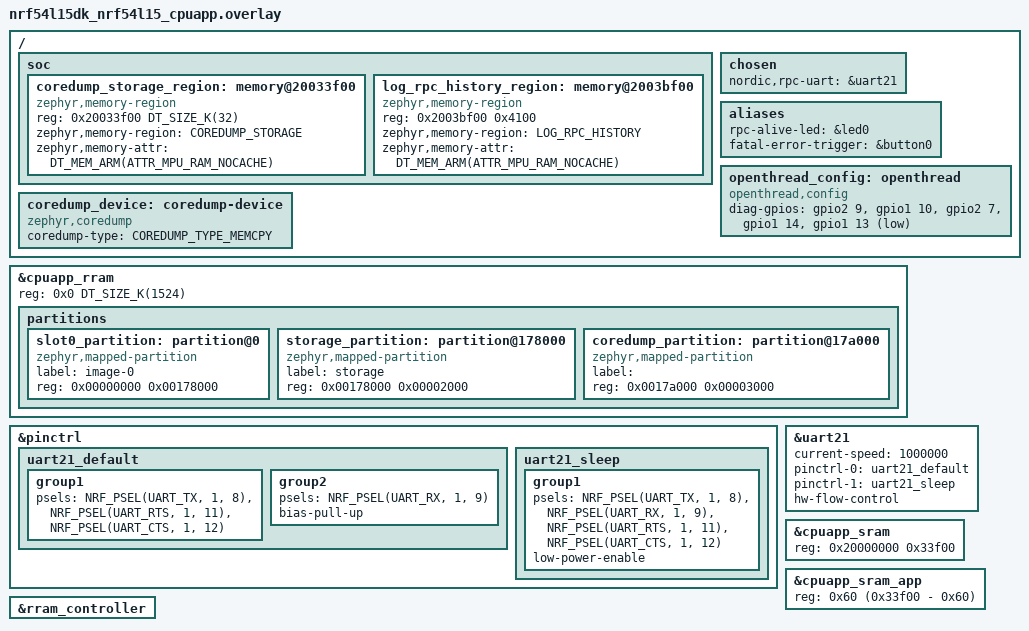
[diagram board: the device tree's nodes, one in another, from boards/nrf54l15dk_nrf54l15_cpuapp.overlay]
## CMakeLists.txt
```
#
# Copyright (c) 2024 Nordic Semiconductor ASA
#
# SPDX-License-Identifier: LicenseRef-Nordic-5-Clause
#
cmake_minimum_required(VERSION 3.20.0)

find_package(Zephyr REQUIRED HINTS $ENV{ZEPHYR_BASE})

# manually enable NRF54L_CONFIGURATION_56_ENABLE until nrfx 4.0.0 is integrated
if ((CONFIG_SOC_SERIES_NRF54LX) AND (CONFIG_NRF_802154_SOURCE_INTERNAL))
    target_compile_definitions(nrf-802154-driver-interface INTERFACE NRF54L_CONFIGURATION_56_ENABLE=1)
endif()

# # Do not include obfuscated symbols in case of building from sources
if (CONFIG_MPSL_BUILD_TYPE_SRC_DEBUG)
  target_compile_definitions(nrf-802154-driver-interface INTERFACE OBFUSCATE_LIBMPSL_PROTOCOL_DEFINES_H__=1)
endif()

project(protocols_serialization_server)

# NORDIC SDK APP START
target_sources(app PRIVATE src/main.c)

if(CONFIG_NRF_PS_SERVER_FATAL_ERROR_TRIGGER)
  target_sources(app PRIVATE src/fatal_error_trigger.c)
endif()


if(CONFIG_NRF_PS_SERVER_HEALTH_MONITOR)
  target_sources(app PRIVATE src/hot_main.c)
endif()

if(CONFIG_NRF_PS_SERVER_RPC_ALIVE_LED)
  # Wrap z_fatal_error to turn off the RPC alive LED on fatal error
  target_link_options(app INTERFACE -Wl,--wrap=z_fatal_error)
endif()
# NORDIC SDK APP END

# Link OpenThread CLI even though OPENTHREAD_SHELL is not selected
if(CONFIG_OPENTHREAD_RPC)
  target_link_libraries(zephyr PRIVATE openthread-cli-ftd)
endif()
```

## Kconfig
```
#
# Copyright (c) 2024 Nordic Semiconductor ASA
#
# SPDX-License-Identifier: LicenseRef-Nordic-5-Clause
#

menu "Protocols serialization server"

config NRF_PS_SERVER_FATAL_ERROR_TRIGGER
	bool "Fatal error trigger"
	depends on $(dt_alias_enabled,fatal-error-trigger)
	help
	  Enables triggering a fatal error by pressing the button selected with
	  "/aliases/fatal-error-trigger" DTS property. This feature can be used
	  to generate a core dump into a flash/RRAM partition. The core dump can
	  then be retrieved by the RPC client using the "Logging over RPC"
	  library.

config NRF_PS_SERVER_RPC_ALIVE_LED
	bool "RPC alive LED"
	default y
	depends on $(dt_alias_enabled,rpc-alive-led)
	help
	  Turns on the LED selected with "/aliases/rpc-alive-led" DTS property
	  when the UART transport is alive and ready to receive nRF RPC packets.

config NRF5_UICR_EUI64_ENABLE
	default y if (SOC_NRF54L15 && OPENTHREAD)

module = NRF_PS_SERVER
module-str = nrf_ps_server
source "$(ZEPHYR_BASE)/subsys/logging/Kconfig.template.log_config"

endmenu # "Protocols serialization server"

config ZMS
	default y if (SOC_FLASH_NRF_RRAM || SOC_FLASH_NRF_MRAM)

config NVS
	default y if !(SOC_FLASH_NRF_RRAM || SOC_FLASH_NRF_MRAM)

config SHELL_BACKEND_SERIAL
	default n if NRF_RPC_UTILS_REMOTE_SHELL

if LOG

choice LOG_MODE
	default LOG_MODE_DEFERRED
endchoice

config LOG_BUFFER_SIZE
	default 8192

config LOG_FUNC_NAME_PREFIX_DBG
	default n

config LOG_BACKEND_RTT
	default n

config LOG_BACKEND_UART
	default n

endif # LOG

if LOG_BACKEND_UART_ASYNC

# Using UART async API by the logging backend significantly reduces CPU load imposed by logging.
# To make it work, the corresponding UART instance needs to be configured to use the async API
# as well, which requires disabling the default, interrupt-driven API.
# Do it for all possible UART instances for the supported nRF54L SoCs.

uart_num = 0
rsource "Kconfig.zephyr_console_async"

uart_num = 1
rsource "Kconfig.zephyr_console_async"

uart_num = 00
rsource "Kconfig.zephyr_console_async"

uart_num = 20
rsource "Kconfig.zephyr_console_async"

uart_num = 21
rsource "Kconfig.zephyr_console_async"

uart_num = 22
rsource "Kconfig.zephyr_console_async"

uart_num = 30
rsource "Kconfig.zephyr_console_async"

endif # LOG_BACKEND_UART_ASYNC

if SOC_NRF54L15

config BT_LONG_WQ_STACK_SIZE
	default 2048

choice TRUSTED_STORAGE_BACKEND_AEAD_KEY
	default TRUSTED_STORAGE_BACKEND_AEAD_KEY_HASH_UID if TRUSTED_STORAGE_BACKEND_AEAD
endchoice

endif # SOC_NRF54L15

menu "Zephyr Kernel"
source "Kconfig.zephyr"
endmenu
```

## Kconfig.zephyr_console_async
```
#
# Copyright (c) 2025 Nordic Semiconductor ASA
#
# SPDX-License-Identifier: LicenseRef-Nordic-5-Clause
#

DT_CHOSEN_ZEPHYR_CONSOLE := zephyr,console

config UART_$(uart_num)_INTERRUPT_DRIVEN
	default n
	depends on $(dt_nodelabel_enabled,uart$(uart_num))
	depends on "$(dt_nodelabel_path,uart$(uart_num))" = "$(dt_chosen_path,$(DT_CHOSEN_ZEPHYR_CONSOLE))"
```

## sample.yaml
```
sample:
  name: Protocols serialization server sample
  description: Demonstrates serialization of Bluetooth LE and OpenThread API using
    nRF RPC

common:
  sysbuild: true
  build_only: true
  platform_allow:
    - nrf54l15dk/nrf54l15/cpuapp
    - nrf54lm20dk/nrf54lm20a/cpuapp
    - nrf54lm20dk/nrf54lm20b/cpuapp
  integration_platforms:
    - nrf54l15dk/nrf54l15/cpuapp
    - nrf54lm20dk/nrf54lm20a/cpuapp
    - nrf54lm20dk/nrf54lm20b/cpuapp
  tags:
    - ci_build
    - ci_samples_nrf_rpc
  extra_args:
    - SNIPPET_ROOT="."

tests:
  sample.nrf_rpc.protocols_serialization.server.rpc_ble:
    extra_args:
      - EXTRA_CONF_FILE=ble.conf
  sample.nrf_rpc.protocols_serialization.server.rpc_ot:
    extra_args:
      - EXTRA_CONF_FILE=openthread.conf
  sample.nrf_rpc.protocols_serialization.server.rpc:
    extra_args:
      - EXTRA_DTC_OVERLAY_FILE=coex.overlay
      - EXTRA_CONF_FILE="ble.conf;openthread.conf;verbose.conf;log_rpc.conf;coex.conf"
  sample.nrf_rpc.protocols_serialization.server.rpc_ci:
    extra_args:
      - SNIPPET="ci-shell"
      - EXTRA_DTC_OVERLAY_FILE=coex.overlay
      - EXTRA_CONF_FILE="ble.conf;openthread.conf;verbose.conf;log_rpc.conf;coex.conf"
    extra_configs:
      - CONFIG_NRF_RPC_UTILS_CRASH_GEN=y
      - CONFIG_OPENTHREAD_RPC_ERASE_SETTINGS=y
```

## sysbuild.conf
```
SB_CONFIG_PARTITION_MANAGER=n
SB_CONFIG_BOOTLOADER_MCUBOOT=y
SB_CONFIG_MCUBOOT_MODE_SINGLE_APP=y
SB_CONFIG_BOOT_SIGNATURE_TYPE_NONE=y
```

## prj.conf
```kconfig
#
# Copyright (c) 2024 Nordic Semiconductor
#
# SPDX-License-Identifier: LicenseRef-Nordic-5-Clause
#
CONFIG_HEAP_MEM_POOL_SIZE=4096

CONFIG_NRF_RPC=y
CONFIG_NRF_RPC_CBOR=y
CONFIG_NRF_RPC_ZCBOR_BACKUPS=1
CONFIG_NRF_RPC_THREAD_STACK_SIZE=4096
CONFIG_NRF_RPC_GROUP_INIT_WAIT_TIME=-1
CONFIG_NRF_RPC_UART_TRANSPORT=y
CONFIG_NRF_RPC_UART_RELIABLE=y

CONFIG_UART_LINE_CTRL=y
CONFIG_UART_INTERRUPT_DRIVEN=y

CONFIG_NRF_RPC_UTILS=y
CONFIG_NRF_RPC_UTILS_SERVER=y
CONFIG_NRF_RPC_UTILS_DEV_INFO=y
CONFIG_NRF_RPC_UTILS_REMOTE_SHELL=y
CONFIG_NRF_RPC_UTILS_SYSTEM_HEALTH=y
CONFIG_NRF_RPC_UTILS_NESTED_CMD_TEST=y

CONFIG_USE_DT_CODE_PARTITION=y
CONFIG_SETTINGS=y
CONFIG_FLASH=y
CONFIG_FLASH_MAP=y
```

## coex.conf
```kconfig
#
# Copyright (c) 2026 Nordic Semiconductor
#
# SPDX-License-Identifier: LicenseRef-Nordic-5-Clause
#
# Enables MPSL Software Coexistence for this sample.
#
# Note: This sample requires applying :file:`coex.overlay` explicitly (pass it
# via EXTRA_DTC_OVERLAY_FILE) together with this Kconfig fragment.
#

CONFIG_MPSL_CX=y
CONFIG_MPSL_CX_SOFTWARE=y
```

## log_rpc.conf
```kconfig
#
# Copyright (c) 2024 Nordic Semiconductor
#
# SPDX-License-Identifier: LicenseRef-Nordic-5-Clause
#

CONFIG_LOG=y
CONFIG_LOG_BACKEND_RPC=y
CONFIG_LOG_BACKEND_RPC_CRASH_LOG=y
CONFIG_LOG_BACKEND_RPC_HISTORY=y
CONFIG_LOG_BACKEND_RPC_ECHO=y

# Core dump in dedicated noinit SRAM (see board overlay coredump_storage_region)
CONFIG_DEBUG_COREDUMP=y
CONFIG_DEBUG_COREDUMP_BACKEND_OTHER=y
CONFIG_DEBUG_COREDUMP_BACKEND_NRF_RAM_REGION=y
CONFIG_DEBUG_COREDUMP_MEMORY_DUMP_THREADS=y
CONFIG_DEBUG_COREDUMP_THREADS_METADATA=y
CONFIG_DEBUG_COREDUMP_THREAD_STACK_TOP=y
CONFIG_DEBUG_COREDUMP_THREAD_STACK_TOP_LIMIT=256
CONFIG_EXTRA_EXCEPTION_INFO=y
CONFIG_COREDUMP_DEVICE=y

# nRF RPC requires slightly bigger stack than default
CONFIG_LOG_PROCESS_THREAD_STACK_SIZE=1024

# Enable OpenThread logs along with logging over RPC
CONFIG_OPENTHREAD_DEBUG=y
CONFIG_OPENTHREAD_LOG_LEVEL_INFO=y

# Enable fatal error trigger for testing the crash log feature
CONFIG_NRF_PS_SERVER_FATAL_ERROR_TRIGGER=y
```

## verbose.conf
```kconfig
#
# Copyright (c) 2024 Nordic Semiconductor
#
# SPDX-License-Identifier: LicenseRef-Nordic-5-Clause
#
# Development-oriented options: asserts, UART logging (async), and DBG level
# for this sample and nRF RPC modules. For manual use, pass e.g.:
#   -- -DEXTRA_CONF_FILE=verbose.conf

# Enable asserts
CONFIG_ASSERT=y

# Enable UART console. Use async API to reduce CPU load.
CONFIG_LOG=y
CONFIG_LOG_BACKEND_UART=y
CONFIG_UART_ASYNC_API=y
CONFIG_LOG_BACKEND_UART_ASYNC=y

# Verbose (DBG) logging for this sample and RPC stack
CONFIG_NRF_PS_SERVER_LOG_LEVEL_DBG=y
CONFIG_NRF_RPC_TR_LOG_LEVEL_DBG=y
CONFIG_NRF_RPC_LOG_LEVEL_DBG=y
CONFIG_NRF_RPC_OS_LOG_LEVEL_DBG=y
CONFIG_NRF_RPC_DETAILED_ERROR_REPORTING=y
CONFIG_NRF_RPC_UTILS_RRAM_WEAR_TEST=y
```

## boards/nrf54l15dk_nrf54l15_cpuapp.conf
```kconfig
#
# Copyright (c) 2024 Nordic Semiconductor
#
# SPDX-License-Identifier: LicenseRef-Nordic-5-Clause
#
CONFIG_MAIN_STACK_SIZE=4196
CONFIG_NRF_RPC_THREAD_STACK_SIZE=6144

# USE HASH UID instead of HUK for this sample, because Partition Manager is not available
CONFIG_TRUSTED_STORAGE_BACKEND_AEAD_KEY_HASH_UID=y

# Workaround required as Zephyr L2 implies usage of NVS backend for settings.
# It should be removed once the proper fix will be applied in Zephyr.
CONFIG_NVS=n
```

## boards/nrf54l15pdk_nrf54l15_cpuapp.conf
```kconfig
#
# Copyright (c) 2024 Nordic Semiconductor
#
# SPDX-License-Identifier: LicenseRef-Nordic-5-Clause
#
CONFIG_MAIN_STACK_SIZE=4196
CONFIG_NRF_RPC_THREAD_STACK_SIZE=6144

# USE HASH UID instead of HUK for this sample, because Partition Manager is not available
CONFIG_TRUSTED_STORAGE_BACKEND_AEAD_KEY_HASH_UID=y
```

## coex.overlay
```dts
/*
 * Copyright (c) 2026 Nordic Semiconductor ASA
 *
 * SPDX-License-Identifier: LicenseRef-Nordic-5-Clause
 */

/ {
	nrf_radio_coex: software-coex {
		compatible = "nordic,software-coex";
		status = "okay";
	};
};
```

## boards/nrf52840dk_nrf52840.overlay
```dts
/*
 * Copyright (c) 2024 Nordic Semiconductor ASA
 *
 * SPDX-License-Identifier: LicenseRef-Nordic-5-Clause
 */
#include <zephyr/dt-bindings/memory-attr/memory-attr-arm.h>

/* Log RPC history + optional RAM coredump. */
/ {
	soc {
		coredump_storage_region: memory@20033f00 {
			compatible = "zephyr,memory-region", "mmio-sram";
			reg = <0x20033f00 DT_SIZE_K(32)>;
			zephyr,memory-region = "COREDUMP_STORAGE";
			zephyr,memory-attr = <DT_MEM_ARM(ATTR_MPU_RAM_NOCACHE)>;
			status = "okay";
		};

		/* 0x4100 = 0x4000 buffer + 0x100 control; ends at 0x20040000 */
		log_rpc_history_region: memory@2003bf00 {
			compatible = "zephyr,memory-region", "mmio-sram";
			reg = <0x2003bf00 0x4100>;
			zephyr,memory-region = "LOG_RPC_HISTORY";
			zephyr,memory-attr = <DT_MEM_ARM(ATTR_MPU_RAM_NOCACHE)>;
			status = "okay";
		};
	};
};

/* Shorter sram0 (0x33f00); 32 KiB COREDUMP_STORAGE; top 0x4100 = log history. */
&sram0 {
	reg = <0x20000000 0x33f00>;
};

/ {
	chosen {
		nordic,rpc-uart = &uart1;
	};

	aliases {
		rpc-alive-led = &led0;
		fatal-error-trigger = &button0;
	};

	openthread_config: openthread {
		compatible = "openthread,config";
		diag-gpios = <&gpio0 13 GPIO_ACTIVE_LOW>,
			     <&gpio0 14 GPIO_ACTIVE_LOW>,
			     <&gpio0 15 GPIO_ACTIVE_LOW>,
			     <&gpio0 16 GPIO_ACTIVE_LOW>,
			     <&gpio0 11 (GPIO_PULL_UP | GPIO_ACTIVE_LOW)>,
			     <&gpio0 12 (GPIO_PULL_UP | GPIO_ACTIVE_LOW)>,
			     <&gpio0 24 (GPIO_PULL_UP | GPIO_ACTIVE_LOW)>,
			     <&gpio0 25 (GPIO_PULL_UP | GPIO_ACTIVE_LOW)>;
	};

	coredump_device: coredump-device {
		compatible = "zephyr,coredump";
		coredump-type = "COREDUMP_TYPE_MEMCPY";
		status = "okay";
	};
};

/delete-node/ &boot_partition;
/delete-node/ &slot0_partition;
/delete-node/ &slot1_partition;
/delete-node/ &storage_partition;

&flash0 {
	partitions {
		slot0_partition: partition@0 {
			compatible = "zephyr,mapped-partition";
			label = "image-0";
			reg = <0x00000000 0x000fb000>;
		};

		storage_partition: partition@fb000 {
			compatible = "zephyr,mapped-partition";
			label = "storage";
			reg = <0x000fb000 0x00002000>;
		};

		coredump_partition: partition@fd000 {
			compatible = "zephyr,mapped-partition";
			label = "";
			reg = <0x000fd000 0x00003000>;
		};
	};
};

&uart1 {
	status = "okay";
	hw-flow-control;
	current-speed = <1000000>;
};

&uart1_default {
	group1 {
		psels = <NRF_PSEL(UART_TX, 1, 2)>,
			<NRF_PSEL(UART_RTS, 1, 3)>,
			<NRF_PSEL(UART_CTS, 1, 4)>;
	};

	group2 {
		psels = <NRF_PSEL(UART_RX, 1, 1)>;
		bias-pull-up;
	};
};

&uart1_sleep {
	group1 {
		psels = <NRF_PSEL(UART_RX, 1, 1)>,
			<NRF_PSEL(UART_TX, 1, 2)>,
			<NRF_PSEL(UART_RTS, 1, 3)>,
			<NRF_PSEL(UART_CTS, 1, 4)>;
		low-power-enable;
	};
};
```

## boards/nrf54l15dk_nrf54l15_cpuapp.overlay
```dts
/*
 * Copyright (c) 2024 Nordic Semiconductor ASA
 *
 * SPDX-License-Identifier: LicenseRef-Nordic-5-Clause
 */

#include <zephyr/dt-bindings/memory-attr/memory-attr-arm.h>

/* Log RPC history: one fixed region (buffer + control + magic) at top of 256 KB SRAM.
 * Layout: [16 KB buffer][pbuf struct + magic]. MPU: non-executable, non-cacheable.
 * Coredump: 32 KB noinit SRAM just below log history
 * (CONFIG_DEBUG_COREDUMP_BACKEND_NRF_RAM_REGION).
 */
/ {
	soc {
		coredump_storage_region: memory@20033f00 {
			compatible = "zephyr,memory-region", "mmio-sram";
			reg = <0x20033f00 DT_SIZE_K(32)>;
			zephyr,memory-region = "COREDUMP_STORAGE";
			zephyr,memory-attr = <DT_MEM_ARM(ATTR_MPU_RAM_NOCACHE)>;
			status = "okay";
		};

		/* 0x4100 = 0x4000 buffer + 0x100 control; base so region ends at 0x20040000 */
		log_rpc_history_region: memory@2003bf00 {
			compatible = "zephyr,memory-region", "mmio-sram";
			reg = <0x2003bf00 0x4100>;
			zephyr,memory-region = "LOG_RPC_HISTORY";
			zephyr,memory-attr = <DT_MEM_ARM(ATTR_MPU_RAM_NOCACHE)>;
			status = "okay";
		};
	};
};

/ {
	chosen {
		nordic,rpc-uart = &uart21;
	};

	aliases {
		rpc-alive-led = &led0;
		fatal-error-trigger = &button0;

		/* delete all buttons except button0 to free GPIO pins assigned to uart21 below */
		/delete-property/ sw1;
		/delete-property/ sw2;
		/delete-property/ sw3;
	};

	openthread_config: openthread {
		compatible = "openthread,config";
		diag-gpios = <&gpio2 9 GPIO_ACTIVE_HIGH>,
			     <&gpio1 10 GPIO_ACTIVE_HIGH>,
			     <&gpio2 7 GPIO_ACTIVE_HIGH>,
			     <&gpio1 14 GPIO_ACTIVE_HIGH>,
			     <&gpio1 13 (GPIO_PULL_UP | GPIO_ACTIVE_LOW)>;
	};

	coredump_device: coredump-device {
		compatible = "zephyr,coredump";
		coredump-type = "COREDUMP_TYPE_MEMCPY";
		status = "okay";
	};
};

/delete-node/ &button1;
/delete-node/ &button2;
/delete-node/ &button3;
/delete-node/ &boot_partition;
/delete-node/ &slot0_partition;
/delete-node/ &slot1_partition;
/delete-node/ &storage_partition;

/* restore full RRAM and SRAM space - by default some parts are dedicated to FLRP */
&cpuapp_rram {
	reg = <0x0 DT_SIZE_K(1524)>;

	partitions {
		slot0_partition: partition@0 {
			compatible = "zephyr,mapped-partition";
			label = "image-0";
			reg = <0x00000000 0x00178000>;
		};

		storage_partition: partition@178000 {
			compatible = "zephyr,mapped-partition";
			label = "storage";
			reg = <0x00178000 0x00002000>;
		};

		coredump_partition: partition@17a000 {
			compatible = "zephyr,mapped-partition";
			label = "";
			reg = <0x0017a000 0x00003000>;
		};
	};
};

&pinctrl {
	uart21_default: uart21_default {
		group1 {
			psels = <NRF_PSEL(UART_TX, 1, 8)>,
				<NRF_PSEL(UART_RTS, 1, 11)>,
				<NRF_PSEL(UART_CTS, 1, 12)>;
		};

		group2 {
			psels = <NRF_PSEL(UART_RX, 1, 9)>;
			bias-pull-up;
		};
	};

	uart21_sleep: uart21_sleep {
		group1 {
			psels = <NRF_PSEL(UART_TX, 1, 8)>,
				<NRF_PSEL(UART_RX, 1, 9)>,
				<NRF_PSEL(UART_RTS, 1, 11)>,
				<NRF_PSEL(UART_CTS, 1, 12)>;
			low-power-enable;
		};
	};
};

&uart21 {
	status = "okay";
	current-speed = <1000000>;
	pinctrl-0 = <&uart21_default>;
	pinctrl-1 = <&uart21_sleep>;
	pinctrl-names = "default", "sleep";
	hw-flow-control;
};

/* restore full RRAM and SRAM space - by default some parts are dedicated to FLRP */
&cpuapp_rram {
	reg = <0x0 DT_SIZE_K(1524)>;
};

/* Shorter cpuapp_sram (0x33f00); 32 KB COREDUMP_STORAGE; top 0x4100 = log history. */
&cpuapp_sram {
	reg = <0x20000000 0x33f00>;
	ranges = <0x0 0x20000000 0x33f00>;
};

&cpuapp_sram_app {
	reg = <0x60 (0x33f00 - 0x60)>;
};

&rram_controller {
	/delete-node/ cpuflpr_sram;
	/delete-node/ cpuflpr_rram;
};
```

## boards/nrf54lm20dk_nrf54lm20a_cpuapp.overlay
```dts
/*
 * Copyright (c) 2025 Nordic Semiconductor ASA
 *
 * SPDX-License-Identifier: LicenseRef-Nordic-5-Clause
 */

#include <zephyr/dt-bindings/memory-attr/memory-attr-arm.h>

/* Log RPC history + RAM coredump at top of cpuapp SRAM. */
/ {
	soc {
		coredump_storage_region: memory@20073b00 {
			compatible = "zephyr,memory-region", "mmio-sram";
			reg = <0x20073b00 DT_SIZE_K(32)>;
			zephyr,memory-region = "COREDUMP_STORAGE";
			zephyr,memory-attr = <DT_MEM_ARM(ATTR_MPU_RAM_NOCACHE)>;
			status = "okay";
		};

		/* Reserve top 0x4100 ending @ 0x2007fc00 */
		log_rpc_history_region: memory@2007bb00 {
			compatible = "zephyr,memory-region", "mmio-sram";
			reg = <0x2007bb00 0x4100>;
			zephyr,memory-region = "LOG_RPC_HISTORY";
			zephyr,memory-attr = <DT_MEM_ARM(ATTR_MPU_RAM_NOCACHE)>;
			status = "okay";
		};
	};
};

/* App SRAM minus coredump and log history (511 KB - 0x8000 - 0x4100 = 0x73b00). */
&cpuapp_sram_app {
	reg = <0x60 (0x73b00 - 0x60)>;
};

/ {
	chosen {
		nordic,rpc-uart = &uart21;
	};

	aliases {
		rpc-alive-led = &led0;
		fatal-error-trigger = &button0;

		/* delete all buttons except button0 to free GPIO pins assigned to uart21 below */
		/delete-property/ sw1;
		/delete-property/ sw2;
		/delete-property/ sw3;
	};

	coredump_device: coredump-device {
		compatible = "zephyr,coredump";
		coredump-type = "COREDUMP_TYPE_MEMCPY";
		status = "okay";
	};
};

/delete-node/ &button1;
/delete-node/ &button2;
/delete-node/ &button3;
/delete-node/ &boot_partition;
/delete-node/ &slot0_partition;
/delete-node/ &slot1_partition;
/delete-node/ &storage_partition;

&cpuapp_rram {
	reg = <0x0 DT_SIZE_K(2036)>;

	partitions {
		slot0_partition: partition@0 {
			compatible = "zephyr,mapped-partition";
			label = "image-0";
			reg = <0x00000000 0x001f8000>;
		};

		storage_partition: partition@1f8000 {
			compatible = "zephyr,mapped-partition";
			label = "storage";
			reg = <0x001f8000 0x00002000>;
		};

		coredump_partition: partition@1fa000 {
			compatible = "zephyr,mapped-partition";
			label = "";
			reg = <0x001fa000 0x00003000>;
		};
	};
};

&pinctrl {
	uart21_default: uart21_default {
		group1 {
			psels = <NRF_PSEL(UART_TX, 1, 8)>,
				<NRF_PSEL(UART_RTS, 1, 11)>,
				<NRF_PSEL(UART_CTS, 1, 12)>;
		};

		group2 {
			psels = <NRF_PSEL(UART_RX, 1, 9)>;
			bias-pull-up;
		};
	};

	uart21_sleep: uart21_sleep {
		group1 {
			psels = <NRF_PSEL(UART_TX, 1, 8)>,
				<NRF_PSEL(UART_RX, 1, 9)>,
				<NRF_PSEL(UART_RTS, 1, 11)>,
				<NRF_PSEL(UART_CTS, 1, 12)>;
			low-power-enable;
		};
	};
};

&uart21 {
	status = "okay";
	current-speed = <1000000>;
	pinctrl-0 = <&uart21_default>;
	pinctrl-1 = <&uart21_sleep>;
	pinctrl-names = "default", "sleep";
	hw-flow-control;
};
```

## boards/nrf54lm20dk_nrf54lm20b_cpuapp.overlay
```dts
/*
 * Copyright (c) 2026 Nordic Semiconductor ASA
 *
 * SPDX-License-Identifier: LicenseRef-Nordic-5-Clause
 */

#include <zephyr/dt-bindings/memory-attr/memory-attr-arm.h>

/* Log RPC history + RAM coredump at top of cpuapp SRAM. */
/ {
	soc {
		coredump_storage_region: memory@20073b00 {
			compatible = "zephyr,memory-region", "mmio-sram";
			reg = <0x20073b00 DT_SIZE_K(32)>;
			zephyr,memory-region = "COREDUMP_STORAGE";
			zephyr,memory-attr = <DT_MEM_ARM(ATTR_MPU_RAM_NOCACHE)>;
			status = "okay";
		};

		/* Reserve top 0x4100 ending @ 0x2007fc00 */
		log_rpc_history_region: memory@2007bb00 {
			compatible = "zephyr,memory-region", "mmio-sram";
			reg = <0x2007bb00 0x4100>;
			zephyr,memory-region = "LOG_RPC_HISTORY";
			zephyr,memory-attr = <DT_MEM_ARM(ATTR_MPU_RAM_NOCACHE)>;
			status = "okay";
		};
	};
};

/* App SRAM minus coredump and log history (511 KB - 0x8000 - 0x4100 = 0x73b00). */
&cpuapp_sram_app {
	reg = <0x60 (0x73b00 - 0x60)>;
};

/ {
	chosen {
		nordic,rpc-uart = &uart21;
	};

	aliases {
		rpc-alive-led = &led0;
		fatal-error-trigger = &button0;

		/* delete all buttons except button0 to free GPIO pins assigned to uart21 below */
		/delete-property/ sw1;
		/delete-property/ sw2;
		/delete-property/ sw3;
	};

	coredump_device: coredump-device {
		compatible = "zephyr,coredump";
		coredump-type = "COREDUMP_TYPE_MEMCPY";
		status = "okay";
	};
};

/delete-node/ &button1;
/delete-node/ &button2;
/delete-node/ &button3;
/delete-node/ &boot_partition;
/delete-node/ &slot0_partition;
/delete-node/ &slot1_partition;
/delete-node/ &storage_partition;

&cpuapp_rram {
	reg = <0x0 DT_SIZE_K(2036)>;

	partitions {
		slot0_partition: partition@0 {
			compatible = "zephyr,mapped-partition";
			label = "image-0";
			reg = <0x00000000 0x001f8000>;
		};

		storage_partition: partition@1f8000 {
			compatible = "zephyr,mapped-partition";
			label = "storage";
			reg = <0x001f8000 0x00002000>;
		};

		coredump_partition: partition@1fa000 {
			compatible = "zephyr,mapped-partition";
			label = "";
			reg = <0x001fa000 0x00003000>;
		};
	};
};

&pinctrl {
	uart21_default: uart21_default {
		group1 {
			psels = <NRF_PSEL(UART_TX, 1, 8)>,
				<NRF_PSEL(UART_RTS, 1, 11)>,
				<NRF_PSEL(UART_CTS, 1, 12)>;
		};

		group2 {
			psels = <NRF_PSEL(UART_RX, 1, 9)>;
			bias-pull-up;
		};
	};

	uart21_sleep: uart21_sleep {
		group1 {
			psels = <NRF_PSEL(UART_TX, 1, 8)>,
				<NRF_PSEL(UART_RX, 1, 9)>,
				<NRF_PSEL(UART_RTS, 1, 11)>,
				<NRF_PSEL(UART_CTS, 1, 12)>;
			low-power-enable;
		};
	};
};

&uart21 {
	status = "okay";
	current-speed = <1000000>;
	pinctrl-0 = <&uart21_default>;
	pinctrl-1 = <&uart21_sleep>;
	pinctrl-names = "default", "sleep";
	hw-flow-control;
};
```

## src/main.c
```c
/*
 * Copyright (c) 2024 Nordic Semiconductor ASA
 *
 * SPDX-License-Identifier: LicenseRef-Nordic-5-Clause
 */

#include <zephyr/drivers/gpio.h>
#include <zephyr/logging/log.h>

#include <nrf_rpc.h>

LOG_MODULE_REGISTER(nrf_ps_server, CONFIG_NRF_PS_SERVER_LOG_LEVEL);

static void err_handler(const struct nrf_rpc_err_report *report)
{
	LOG_ERR("nRF RPC error %d ocurred. See nRF RPC logs for more details", report->code);
}

#ifdef CONFIG_NRF_PS_SERVER_RPC_ALIVE_LED
void nrf_rpc_uart_initialized_hook(const struct device *uart_dev)
{
	const struct gpio_dt_spec alive_gpio = GPIO_DT_SPEC_GET(DT_ALIAS(rpc_alive_led), gpios);
	int ret;

	__ASSERT_NO_MSG(uart_dev == DEVICE_DT_GET(DT_CHOSEN(nordic_rpc_uart)));
	ret = gpio_pin_configure_dt(&alive_gpio, GPIO_OUTPUT_ACTIVE);

	if (ret) {
		LOG_ERR("Failed to configure RPC alive GPIO: %d", ret);
	}
}

void __real_z_fatal_error(unsigned int reason, const struct arch_esf *esf);

void __wrap_z_fatal_error(unsigned int reason, const struct arch_esf *esf)
{
	const struct gpio_dt_spec alive_gpio = GPIO_DT_SPEC_GET(DT_ALIAS(rpc_alive_led), gpios);

	(void)gpio_pin_configure_dt(&alive_gpio, GPIO_OUTPUT_INACTIVE);

	__real_z_fatal_error(reason, esf);
}
#endif

int main(void)
{
	int ret;

	LOG_INF("Initializing RPC server");

	ret = nrf_rpc_init(err_handler);

	if (ret != 0) {
		LOG_ERR("RPC init failed");
	}

	LOG_INF("RPC server ready");

	return 0;
}
```

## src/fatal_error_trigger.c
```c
/*
 * Copyright (c) 2024 Nordic Semiconductor ASA
 *
 * SPDX-License-Identifier: LicenseRef-Nordic-5-Clause
 */

#include <zephyr/drivers/gpio.h>
#include <zephyr/init.h>
#include <zephyr/logging/log.h>
#include <zephyr/sys/util_macro.h>

LOG_MODULE_DECLARE(nrf_ps_server, CONFIG_NRF_PS_SERVER_LOG_LEVEL);

const struct gpio_dt_spec gpio_pin = GPIO_DT_SPEC_GET(DT_ALIAS(fatal_error_trigger), gpios);
static struct gpio_callback gpio_cb;

static void trigger_handler(const struct device *port, struct gpio_callback *cb,
			    gpio_port_pins_t pins)
{
	ARG_UNUSED(port);
	ARG_UNUSED(cb);
	ARG_UNUSED(pins);

	LOG_ERR("Fatal error button pressed - triggering k_oops");
	k_oops();
}

static int trigger_init(void)
{
	int rc;

	if (!gpio_is_ready_dt(&gpio_pin)) {
		return -ENODEV;
	}

	rc = gpio_pin_configure_dt(&gpio_pin, GPIO_INPUT);
	if (rc) {
		return rc;
	}

	gpio_init_callback(&gpio_cb, trigger_handler, BIT(gpio_pin.pin));

	rc = gpio_add_callback_dt(&gpio_pin, &gpio_cb);
	if (rc) {
		return rc;
	}

	rc = gpio_pin_interrupt_configure_dt(&gpio_pin, GPIO_INT_EDGE_TO_ACTIVE);
	if (rc) {
		return rc;
	}

	return 0;
}

SYS_INIT(trigger_init, APPLICATION, CONFIG_APPLICATION_INIT_PRIORITY);
```

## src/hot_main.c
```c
/*
 * Copyright (c) 2024 Nordic Semiconductor ASA
 *
 * SPDX-License-Identifier: LicenseRef-Nordic-5-Clause
 */

#include <zephyr/kernel.h>
#include <zephyr/logging/log.h>
#include <health_monitor.h>

LOG_MODULE_REGISTER(nrf_ps_server_main, CONFIG_NRF_PS_SERVER_LOG_LEVEL);


#define WORK_STACK_SIZE 1024
#define WORK_PRIORITY   K_LOWEST_APPLICATION_THREAD_PRIO

K_THREAD_STACK_DEFINE(hotpot_workqueue_stack, WORK_STACK_SIZE);

struct k_work_q hotpork_workq;

static int init_hotpot_workqueue(void)
{
	k_work_queue_init(&hotpork_workq);

	k_work_queue_start(&hotpork_workq,
			    hotpot_workqueue_stack,
			    K_THREAD_STACK_SIZEOF(hotpot_workqueue_stack),
			    WORK_PRIORITY,
			    NULL);

	health_monitor_init(&hotpork_workq);

	LOG_INF("Initialized application workqueue.");

	return 0;
}

SYS_INIT(init_hotpot_workqueue, APPLICATION, CONFIG_APPLICATION_INIT_PRIORITY);
```
